# ESP32-C5 register map
Vendor: ESPRESSIF SYSTEMS (SHANGHAI) CO., LTD.; Series: ESP32 C-Series; File version: 1
CPU: RV32IMAC r0p0, little endian, no MPU, no FPU, 0 interrupt priority bits
Address unit: 32 bits
Registers are 32-bit, read-write, reset 0x0 unless marked. A register's access mark holds for its fields unless they carry their own. Offsets are from the block's base; [hi:lo] are bit positions; {n}, {i} and the like mark numbered series.

## HINF
Base 0x60016000
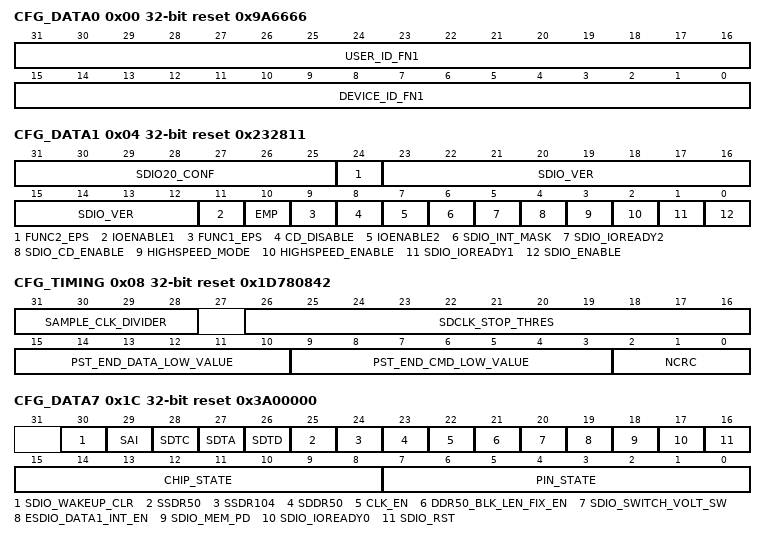
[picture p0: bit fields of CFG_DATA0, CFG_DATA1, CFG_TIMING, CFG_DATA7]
0x00 CFG_DATA0 reset 0x9A6666
  [31:16] USER_ID_FN1, [15:0] DEVICE_ID_FN1
0x04 CFG_DATA1 reset 0x232811
  [31:25] SDIO20_CONF, [24] FUNC2_EPS ro, [23:12] SDIO_VER, [11] IOENABLE1 ro, [10] EMP ro, [9] FUNC1_EPS ro, [8] CD_DISABLE ro, [7] IOENABLE2 ro, [6] SDIO_INT_MASK, [5] SDIO_IOREADY2, [4] SDIO_CD_ENABLE, [3] HIGHSPEED_MODE ro, [2] HIGHSPEED_ENABLE, [1] SDIO_IOREADY1, [0] SDIO_ENABLE
0x08 CFG_TIMING reset 0x1D780842
  [31:28] SAMPLE_CLK_DIVIDER, [26:16] SDCLK_STOP_THRES, [15:10] PST_END_DATA_LOW_VALUE, [9:3] PST_END_CMD_LOW_VALUE, [2:0] NCRC
0x0C CFG_UPDATE wo
  [0] CONF_UPDATE
0x1C CFG_DATA7 reset 0x3A00000
  [30] SDIO_WAKEUP_CLR, [29] SAI, [28] SDTC, [27] SDTA, [26] SDTD, [25] SSDR50, [24] SSDR104, [23] SDDR50, [22] CLK_EN, [21] DDR50_BLK_LEN_FIX_EN, [20] SDIO_SWITCH_VOLT_SW, [19] ESDIO_DATA1_INT_EN, [18] SDIO_MEM_PD, [17] SDIO_IOREADY0, [16] SDIO_RST, [15:8] CHIP_STATE, [7:0] PIN_STATE
{0x20+4i} CIS_CONF_W{i} (i=0..7) reset 0xFFFFFFFF — SDIO cis configuration register
  [31:0] CIS_CONF_W — Configure cis addr 39~36
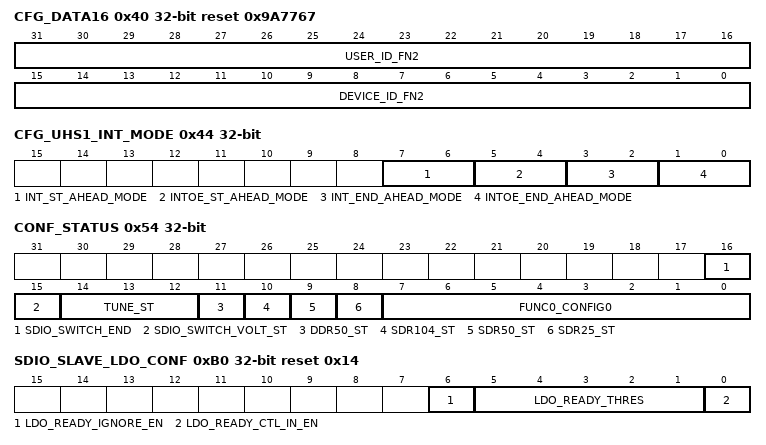
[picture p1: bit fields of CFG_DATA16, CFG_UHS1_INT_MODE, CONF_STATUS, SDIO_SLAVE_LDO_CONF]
0x40 CFG_DATA16 reset 0x9A7767
  [31:16] USER_ID_FN2, [15:0] DEVICE_ID_FN2
0x44 CFG_UHS1_INT_MODE
  [7:6] INT_ST_AHEAD_MODE, [5:4] INTOE_ST_AHEAD_MODE, [3:2] INT_END_AHEAD_MODE, [1:0] INTOE_END_AHEAD_MODE
0x54 CONF_STATUS ro
  [16] SDIO_SWITCH_END, [15] SDIO_SWITCH_VOLT_ST, [14:12] TUNE_ST, [11] DDR50_ST, [10] SDR104_ST, [9] SDR50_ST, [8] SDR25_ST, [7:0] FUNC0_CONFIG0
0xB0 SDIO_SLAVE_LDO_CONF reset 0x14
  [6] LDO_READY_IGNORE_EN, [5:1] LDO_READY_THRES, [0] LDO_READY_CTL_IN_EN
0xFC SDIO_DATE

## PAU — PAU Peripheral
Base 0x60093000
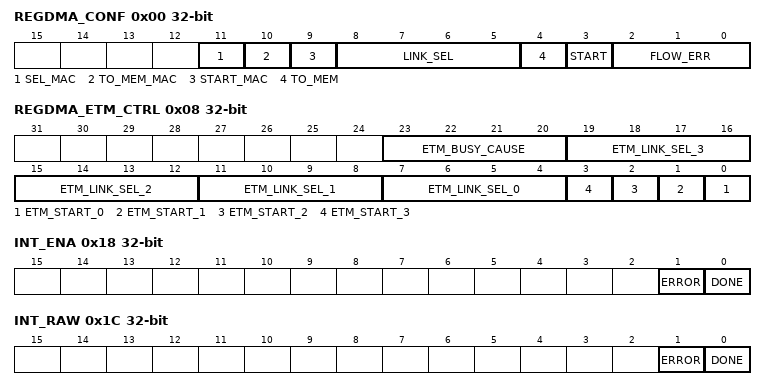
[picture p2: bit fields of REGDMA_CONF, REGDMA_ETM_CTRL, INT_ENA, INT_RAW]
0x00 REGDMA_CONF access per field — Peri backup control register
  [11] SEL_MAC rw — mac hw/sw select
  [10] TO_MEM_MAC rw — mac sw backup direction(reg to mem / mem to reg)
  [9] START_MAC wo — mac sw backup start signal
  [8:5] LINK_SEL rw — Link select
  [4] TO_MEM rw — backup direction(reg to mem / mem to reg)
  [3] START wo — backup start signal
  [2:0] FLOW_ERR ro — backup error type
0x04 REGDMA_CLK_CONF — Clock control register
  [0] CLK_EN — clock enable
0x08 REGDMA_ETM_CTRL access per field — ETM start ctrl reg
  [23:20] ETM_BUSY_CAUSE ro — debug
  [4n+7:4n+4] ETM_LINK_SEL_{n} rw (n=0..3) — etm_link sel
  [n] ETM_START_{n} wo (n=0..3) — etm_start_{n} reg
0x0C REGDMA_CURRENT_LINK_ADDR ro — current link addr
  [31:0] CURRENT_LINK_ADDR — current link addr reg
0x10 REGDMA_PERI_ADDR ro — Backup addr
  [31:0] PERI_ADDR — peri addr reg
0x14 REGDMA_MEM_ADDR ro — mem addr
  [31:0] MEM_ADDR — mem addr reg
0x18 INT_ENA — Read only register for error and done
  [1] ERROR — error flag
  [0] DONE — backup done flag
0x1C INT_RAW — Read only register for error and done
  [1] ERROR — error flag
  [0] DONE — backup done flag
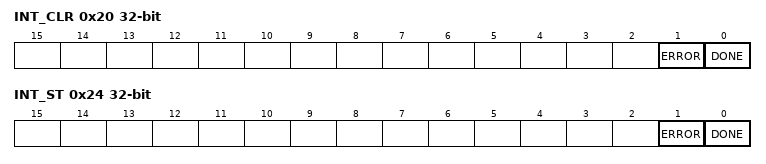
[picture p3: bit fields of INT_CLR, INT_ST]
0x20 INT_CLR wo — Read only register for error and done
  [1] ERROR write-1-clears — error flag
  [0] DONE write-1-clears — backup done flag
0x24 INT_ST ro — Read only register for error and done
  [1] ERROR — error flag
  [0] DONE — backup done flag
0x3FC DATE

## RNG — Hardware Random Number Generator
Base 0x600B2800
0x08 DATA access not given — Random number data

## RSA — RSA (Rivest Shamir Adleman) Accelerator
Base 0x6008A000
{0x0+4i} M_MEM[{i}] (i=0..95) — Represents M
{0x200+4i} Z_MEM[{i}] (i=0..95) — Represents Z
{0x400+4i} Y_MEM[{i}] (i=0..95) — Represents Y
{0x600+4i} X_MEM[{i}] (i=0..95) — Represents X
0x800 M_PRIME — Represents M'
0x804 MODE — Configures RSA length
  [6:0] MODE — Configures the RSA length.
0x808 QUERY_CLEAN ro — RSA initialization status
  [0] QUERY_CLEAN — Represents whether or not the RSA memory completes initialization.\\ 0: Not complete\\ 1: Completed\\
0x80C SET_START_MODEXP wo — Starts modular exponentiation
  [0] SET_START_MODEXP — Configures whether or not to starts the modular exponentiation. \\ 0: No effect\\ 1: Start\\
0x810 SET_START_MODMULT wo — Starts modular multiplication
  [0] SET_START_MODMULT — Configures whether or not to start the modular multiplication.\\ 0: No effect\\ 1: Start\\
0x814 SET_START_MULT wo — Starts multiplication
  [0] SET_START_MULT — Configures whether or not to start the multiplication.\\ 0: No effect\\ 1: Start\\
0x818 QUERY_IDLE ro — Represents the RSA status
  [0] QUERY_IDLE — Represents the RSA status.\\ 0: Busy\\ 1: Idle\\
0x81C INT_CLR — Clears RSA interrupt
  [0] INT_CLR — Write 1 to clear the RSA interrupt.
0x820 CONSTANT_TIME reset 0x1 — Configures the constant_time option
  [0] CONSTANT_TIME — Configures the constant_time option. \\ 0: Acceleration\\ 1: No acceleration (default)\\
0x824 SEARCH_ENABLE — Configures the search option
  [0] SEARCH_ENABLE — Configures the search option. \\ 0: No acceleration (default)\\ 1: Acceleration\\ This option should be used together with RSA_SEARCH_POS_REG.
0x828 SEARCH_POS — Configures the search position
  [11:0] SEARCH_POS — Configures the starting address to start search. This field should be used together with RSA_SEARCH_ENABLE_REG. The field is only valid when RSA_SEARCH_ENABLE is high.
0x82C INT_ENA — Enables the RSA interrupt
  [0] INT_ENA — Write 1 to enable the RSA interrupt.
0x830 DATE — Version control register
